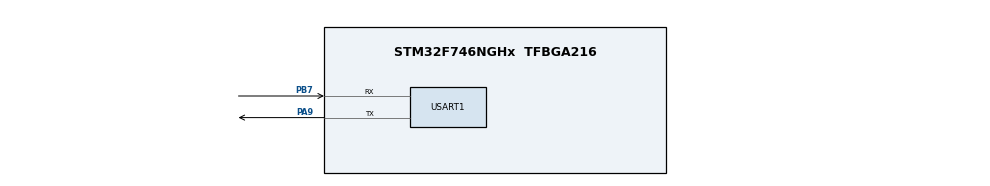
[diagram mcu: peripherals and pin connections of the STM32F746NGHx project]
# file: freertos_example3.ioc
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CORTEX_M7.default_mode_Activation=1
FREERTOS.Tasks01=defaultTask,24,128,StartDefaultTask,Default,NULL,Dynamic,NULL,NULL
Mcu.Family=STM32F7
Mcu.Name=STM32F746NGHx
Mcu.Package=TFBGA216
NVIC.PriorityGroup=NVIC_PRIORITYGROUP_4
NVIC.USART1_IRQn=true\:5\:0\:false\:false\:true\:true\:true\:true\:true
PA9.Mode=Asynchronous
PA9.Signal=USART1_TX
PB7.Mode=Asynchronous
PB7.Signal=USART1_RX
ProjectManager.HeapSize=0x200
ProjectManager.StackSize=0x400
ProjectManager.TargetToolchain=STM32CubeIDE
RCC.HSE_VALUE=25000000
RCC.HSI_VALUE=16000000
RCC.LSE_VALUE=32768
RCC.USBFreq_Value=96000000
RCC.VCOOutputFreq_Value=192000000
USART1.VirtualMode-Asynchronous=VM_ASYNC
VP_FREERTOS_VS_CMSIS_V2.Mode=CMSIS_V2
board=custom

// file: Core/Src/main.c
/* USER CODE BEGIN Header */
/**
  ******************************************************************************
  * @file           : main.c
  * @brief          : Main program body
  ******************************************************************************
  * @attention
  *
  * Copyright (c) 2025 STMicroelectronics.
  * All rights reserved.
  *
  * This software is licensed under terms that can be found in the LICENSE file
  * in the root directory of this software component.
  * If no LICENSE file comes with this software, it is provided AS-IS.
  *
  ******************************************************************************
  */
/* USER CODE END Header */
#include "main.h"
#include "cmsis_os.h"
#include "printf.h"
#include "FreeRTOS.h"
#include "queue.h"

/* Definitions for defaultTask */
osThreadId_t defaultTaskHandle;

/* USER CODE BEGIN PV */

QueueHandle_t msg_queue;
void userTask(void *argument);

/* USER CODE END PV */

void SystemClock_Config(void);
static void MPU_Config(void);
static void MX_GPIO_Init(void);
static void MX_USART1_UART_Init(void);
void StartDefaultTask(void *argument);

int main(void)
{

  /* MPU Configuration--------------------------------------------------------*/
  MPU_Config();

  /* MCU Configuration--------------------------------------------------------*/

  /* Reset of all peripherals, Initializes the Flash interface and the Systick. */
  LL_APB1_GRP1_EnableClock(LL_APB1_GRP1_PERIPH_PWR);
  LL_APB2_GRP1_EnableClock(LL_APB2_GRP1_PERIPH_SYSCFG);

  /* System interrupt init*/
  NVIC_SetPriorityGrouping(NVIC_PRIORITYGROUP_4);

  /* PendSV_IRQn interrupt configuration */
  NVIC_SetPriority(PendSV_IRQn, NVIC_EncodePriority(NVIC_GetPriorityGrouping(),15, 0));
  /* SysTick_IRQn interrupt configuration */
  NVIC_SetPriority(SysTick_IRQn, NVIC_EncodePriority(NVIC_GetPriorityGrouping(),15, 0));

  /* Configure the system clock */
  SystemClock_Config();

  /* Initialize all configured peripherals */
  MX_GPIO_Init();
  MX_USART1_UART_Init();

  /* Init scheduler */
  osKernelInitialize();

  /* Create the thread(s) */
  /* creation of defaultTask */
 //efaultTaskHandle = osThreadNew(StartDefaultTask, NULL, &defaultTask_attributes);

  /* Start scheduler */
 //sKernelStart();

  /* We should never get here as control is now taken by the scheduler */

  /* Infinite loop */
  /* USER CODE BEGIN WHILE */
  msg_queue = xQueueCreate(5, sizeof(messsage_t));
  BaseType_t ret = xTaskCreate(
	 StartDefaultTask,           // Task function
      "StartDefaultTask",          // Name (for debug)
      256,               // Stack depth (words, not bytes on Cortex-M)
      NULL,              // Parameters
      (UBaseType_t)2,    // Priority = 1
      NULL               // Task handle (optional)
  );
  ret = xTaskCreate(
		userTask,           // Task function
        "UserTask",
        256,               // Stack depth (words, not bytes on Cortex-M)
        NULL,              // Parameters
        (UBaseType_t)1,   // Priority = 1
        NULL               // Task handle (optional)
    );
  vTaskStartScheduler();

  while (1)
  {

    /* USER CODE END WHILE */

  }
}

void SystemClock_Config(void)
{
  LL_FLASH_SetLatency(LL_FLASH_LATENCY_0);
  while(LL_FLASH_GetLatency()!= LL_FLASH_LATENCY_0)
  {
  }
  LL_PWR_SetRegulVoltageScaling(LL_PWR_REGU_VOLTAGE_SCALE3);
  LL_PWR_DisableOverDriveMode();
  LL_RCC_HSI_SetCalibTrimming(16);
  LL_RCC_HSI_Enable();

   /* Wait till HSI is ready */
  while(LL_RCC_HSI_IsReady() != 1)
  {

  }
  LL_RCC_SetAHBPrescaler(LL_RCC_SYSCLK_DIV_1);
  LL_RCC_SetAPB1Prescaler(LL_RCC_APB1_DIV_1);
  LL_RCC_SetAPB2Prescaler(LL_RCC_APB2_DIV_1);
  LL_RCC_SetSysClkSource(LL_RCC_SYS_CLKSOURCE_HSI);

   /* Wait till System clock is ready */
  while(LL_RCC_GetSysClkSource() != LL_RCC_SYS_CLKSOURCE_STATUS_HSI)
  {

  }
  LL_Init1msTick(16000000);
  LL_SetSystemCoreClock(16000000);

   /* Set Timers Clock Prescalers */
  LL_RCC_SetTIMPrescaler(LL_RCC_TIM_PRESCALER_TWICE);
}

static void MX_USART1_UART_Init(void)
{

  LL_USART_InitTypeDef USART_InitStruct = {0};

  LL_GPIO_InitTypeDef GPIO_InitStruct = {0};

  LL_RCC_SetUSARTClockSource(LL_RCC_USART1_CLKSOURCE_PCLK2);

  /* Peripheral clock enable */
  LL_APB2_GRP1_EnableClock(LL_APB2_GRP1_PERIPH_USART1);

  LL_AHB1_GRP1_EnableClock(LL_AHB1_GRP1_PERIPH_GPIOB);
  LL_AHB1_GRP1_EnableClock(LL_AHB1_GRP1_PERIPH_GPIOA);
  /**USART1 GPIO Configuration
  PB7   ------> USART1_RX
  PA9   ------> USART1_TX
  */
  GPIO_InitStruct.Pin = LL_GPIO_PIN_7;
  GPIO_InitStruct.Mode = LL_GPIO_MODE_ALTERNATE;
  GPIO_InitStruct.Speed = LL_GPIO_SPEED_FREQ_VERY_HIGH;
  GPIO_InitStruct.OutputType = LL_GPIO_OUTPUT_PUSHPULL;
  GPIO_InitStruct.Pull = LL_GPIO_PULL_NO;
  GPIO_InitStruct.Alternate = LL_GPIO_AF_7;
  LL_GPIO_Init(GPIOB, &GPIO_InitStruct);

  GPIO_InitStruct.Pin = LL_GPIO_PIN_9;
  GPIO_InitStruct.Mode = LL_GPIO_MODE_ALTERNATE;
  GPIO_InitStruct.Speed = LL_GPIO_SPEED_FREQ_VERY_HIGH;
  GPIO_InitStruct.OutputType = LL_GPIO_OUTPUT_PUSHPULL;
  GPIO_InitStruct.Pull = LL_GPIO_PULL_NO;
  GPIO_InitStruct.Alternate = LL_GPIO_AF_7;
  LL_GPIO_Init(GPIOA, &GPIO_InitStruct);

  /* USART1 interrupt Init */
  NVIC_SetPriority(USART1_IRQn, NVIC_EncodePriority(NVIC_GetPriorityGrouping(),5, 0));
  NVIC_EnableIRQ(USART1_IRQn);

  /* USER CODE BEGIN USART1_Init 1 */
  LL_USART_EnableIT_RXNE(USART1);
  /* USER CODE END USART1_Init 1 */
  USART_InitStruct.BaudRate = 115200;
  USART_InitStruct.DataWidth = LL_USART_DATAWIDTH_8B;
  USART_InitStruct.StopBits = LL_USART_STOPBITS_1;
  USART_InitStruct.Parity = LL_USART_PARITY_NONE;
  USART_InitStruct.TransferDirection = LL_USART_DIRECTION_TX_RX;
  USART_InitStruct.HardwareFlowControl = LL_USART_HWCONTROL_NONE;
  USART_InitStruct.OverSampling = LL_USART_OVERSAMPLING_16;
  LL_USART_Init(USART1, &USART_InitStruct);
  LL_USART_ConfigAsyncMode(USART1);
  LL_USART_Enable(USART1);

}

static void MX_GPIO_Init(void)
{

  /* GPIO Ports Clock Enable */
  LL_AHB1_GRP1_EnableClock(LL_AHB1_GRP1_PERIPH_GPIOB);
  LL_AHB1_GRP1_EnableClock(LL_AHB1_GRP1_PERIPH_GPIOA);

}

/* USER CODE BEGIN 4 */
void userTask(void *argument)
{
  /* USER CODE BEGIN 5 */
  /* Infinite loop */

  for(;;)
  {
	  taskENTER_CRITICAL();
	  printf("task 1 is running\r\n");
	  taskEXIT_CRITICAL();
	  taskYIELD();

  }
  /* USER CODE END 5 */
}

/* USER CODE END 4 */

void StartDefaultTask(void *argument)
{
  /* USER CODE BEGIN 5 */
  /* Infinite loop */

  for(;;)
  {

	  taskENTER_CRITICAL();
	  printf("task 2 is running\r\n");
	  taskEXIT_CRITICAL();
	  taskYIELD();
  }
  /* USER CODE END 5 */
}

 /* MPU Configuration */

void MPU_Config(void)
{

  /* Disables the MPU */
  LL_MPU_Disable();

  /** Initializes and configures the Region and the memory to be protected
  */
  LL_MPU_ConfigRegion(LL_MPU_REGION_NUMBER0, 0x87, 0x0, LL_MPU_REGION_SIZE_4GB|LL_MPU_TEX_LEVEL0|LL_MPU_REGION_NO_ACCESS|LL_MPU_INSTRUCTION_ACCESS_DISABLE|LL_MPU_ACCESS_SHAREABLE|LL_MPU_ACCESS_NOT_CACHEABLE|LL_MPU_ACCESS_NOT_BUFFERABLE);
  /* Enables the MPU */
  LL_MPU_Enable(LL_MPU_CTRL_PRIVILEGED_DEFAULT);

}

void Error_Handler(void)
{
  __disable_irq();
  while (1)
  {
  }
}
